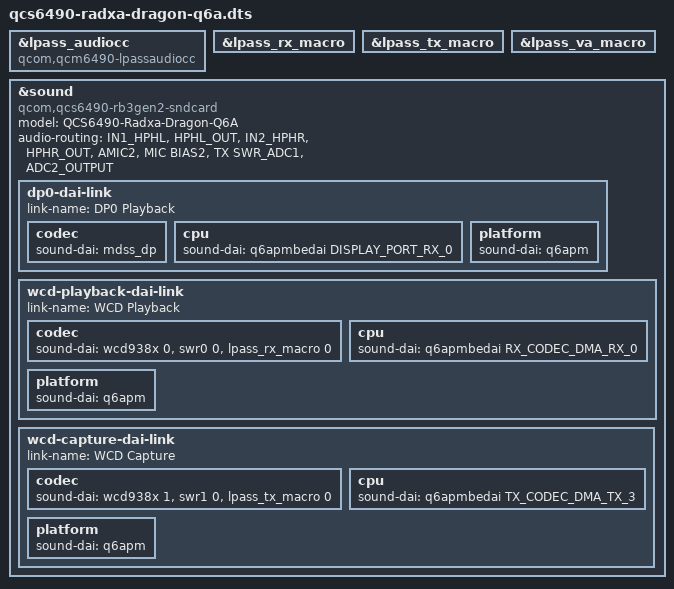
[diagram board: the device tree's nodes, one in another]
// SPDX-License-Identifier: BSD-3-Clause
/*
 * Copyright (c) 2025-2026 Radxa Computer (Shenzhen) Co., Ltd.
 */

/dts-v1/;

#include "qcs6490-radxa-dragon-q6a.dtsi"
#include "qcs6490-audioreach.dtsi"

&lpass_audiocc {
	compatible = "qcom,qcm6490-lpassaudiocc";
	/delete-property/ power-domains;
};

&lpass_rx_macro {
	status = "okay";
};

&lpass_tx_macro {
	status = "okay";
};

&lpass_va_macro {
	status = "okay";
};

&sound {
	compatible = "qcom,qcs6490-rb3gen2-sndcard";
	model = "QCS6490-Radxa-Dragon-Q6A";

	audio-routing = "IN1_HPHL", "HPHL_OUT",
			"IN2_HPHR", "HPHR_OUT",
			"AMIC2", "MIC BIAS2",
			"TX SWR_ADC1", "ADC2_OUTPUT";

	dp0-dai-link {
		link-name = "DP0 Playback";

		codec {
			sound-dai = <&mdss_dp>;
		};

		cpu {
			sound-dai = <&q6apmbedai DISPLAY_PORT_RX_0>;
		};

		platform {
			sound-dai = <&q6apm>;
		};
	};

	wcd-playback-dai-link {
		link-name = "WCD Playback";

		codec {
			sound-dai = <&wcd938x 0>, <&swr0 0>, <&lpass_rx_macro 0>;
		};

		cpu {
			sound-dai = <&q6apmbedai RX_CODEC_DMA_RX_0>;
		};

		platform {
			sound-dai = <&q6apm>;
		};
	};

	wcd-capture-dai-link {
		link-name = "WCD Capture";

		codec {
			sound-dai = <&wcd938x 1>, <&swr1 0>, <&lpass_tx_macro 0>;
		};

		cpu {
			sound-dai = <&q6apmbedai TX_CODEC_DMA_TX_3>;
		};

		platform {
			sound-dai = <&q6apm>;
		};
	};
};
